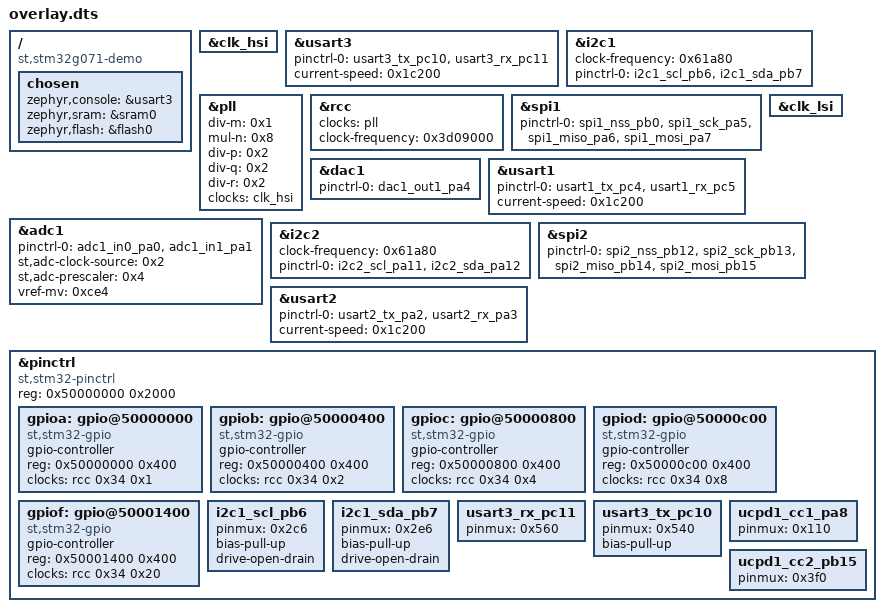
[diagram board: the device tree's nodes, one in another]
/ {
	compatible = "st,stm32g071-demo";
	chosen {
		zephyr,console = &usart3;
		zephyr,sram = &sram0;
		zephyr,flash = &flash0;
	};
};
&clk_hsi{
	status = "okay";
};
&usart3{
	status = "okay";
	pinctrl-0 = < &usart3_tx_pc10 &usart3_rx_pc11 >;
	pinctrl-names = "default";
	current-speed = < 0x1c200 >;
};
&i2c1{
	clock-frequency = < 0x61a80 >;
	status = "okay";
	pinctrl-0 = < &i2c1_scl_pb6 &i2c1_sda_pb7 >;
	pinctrl-names = "default";
};
&pll{
	status = "okay";
	div-m = < 0x1 >;
	mul-n = < 0x8 >;
	div-p = < 0x2 >;
	div-q = < 0x2 >;
	div-r = < 0x2 >;
	clocks = < &clk_hsi >;
};
&rcc{
	clocks = < &pll >;
	clock-frequency = < 0x3d09000 >;
};
&spi1{
	status = "okay";
	pinctrl-0 = < &spi1_nss_pb0 &spi1_sck_pa5 &spi1_miso_pa6 &spi1_mosi_pa7 >;
	pinctrl-names = "default";
};
&dac1{
	status = "okay";
	pinctrl-0 = < &dac1_out1_pa4 >;
	pinctrl-names = "default";
};
&usart1{
	status = "okay";
	pinctrl-0 = < &usart1_tx_pc4 &usart1_rx_pc5 >;
	pinctrl-names = "default";
	current-speed = < 0x1c200 >;
};
&clk_lsi{
	status = "okay";
};
&adc1{
	status = "okay";
	pinctrl-0 = < &adc1_in0_pa0 &adc1_in1_pa1 >;
	pinctrl-names = "default";
	st,adc-clock-source = < 0x2 >;
	st,adc-prescaler = < 0x4 >;
	vref-mv = < 0xce4 >;
};
&i2c2{
	clock-frequency = < 0x61a80 >;
	status = "okay";
	pinctrl-0 = < &i2c2_scl_pa11 &i2c2_sda_pa12 >;
	pinctrl-names = "default";
};
&spi2{
	status = "okay";
	pinctrl-0 = < &spi2_nss_pb12 &spi2_sck_pb13 &spi2_miso_pb14 &spi2_mosi_pb15 >;
	pinctrl-names = "default";
};
&usart2{
	status = "okay";
	pinctrl-0 = < &usart2_tx_pa2 &usart2_rx_pa3 >;
	pinctrl-names = "default";
	current-speed = < 0x1c200 >;
};
&pinctrl{
	compatible = "st,stm32-pinctrl";
	#address-cells = < 0x1 >;
	#size-cells = < 0x1 >;
	reg = < 0x50000000 0x2000 >;
	gpioa: gpio@50000000 {
		compatible = "st,stm32-gpio";
		gpio-controller;
		#gpio-cells = < 0x2 >;
		reg = < 0x50000000 0x400 >;
		clocks = < &rcc 0x34 0x1 >;
	};
	gpiob: gpio@50000400 {
		compatible = "st,stm32-gpio";
		gpio-controller;
		#gpio-cells = < 0x2 >;
		reg = < 0x50000400 0x400 >;
		clocks = < &rcc 0x34 0x2 >;
	};
	gpioc: gpio@50000800 {
		compatible = "st,stm32-gpio";
		gpio-controller;
		#gpio-cells = < 0x2 >;
		reg = < 0x50000800 0x400 >;
		clocks = < &rcc 0x34 0x4 >;
	};
	gpiod: gpio@50000c00 {
		compatible = "st,stm32-gpio";
		gpio-controller;
		#gpio-cells = < 0x2 >;
		reg = < 0x50000c00 0x400 >;
		clocks = < &rcc 0x34 0x8 >;
	};
	gpiof: gpio@50001400 {
		compatible = "st,stm32-gpio";
		gpio-controller;
		#gpio-cells = < 0x2 >;
		reg = < 0x50001400 0x400 >;
		clocks = < &rcc 0x34 0x20 >;
	};
	i2c1_scl_pb6: i2c1_scl_pb6 {
		pinmux = < 0x2c6 >;
		bias-pull-up;
		drive-open-drain;
	};
	i2c1_sda_pb7: i2c1_sda_pb7 {
		pinmux = < 0x2e6 >;
		bias-pull-up;
		drive-open-drain;
	};
	usart3_rx_pc11: usart3_rx_pc11 {
		pinmux = < 0x560 >;
	};
	usart3_tx_pc10: usart3_tx_pc10 {
		pinmux = < 0x540 >;
		bias-pull-up;
	};
	ucpd1_cc1_pa8: ucpd1_cc1_pa8 {
		pinmux = < 0x110 >;
	};
	ucpd1_cc2_pb15: ucpd1_cc2_pb15 {
		pinmux = < 0x3f0 >;
	};
};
